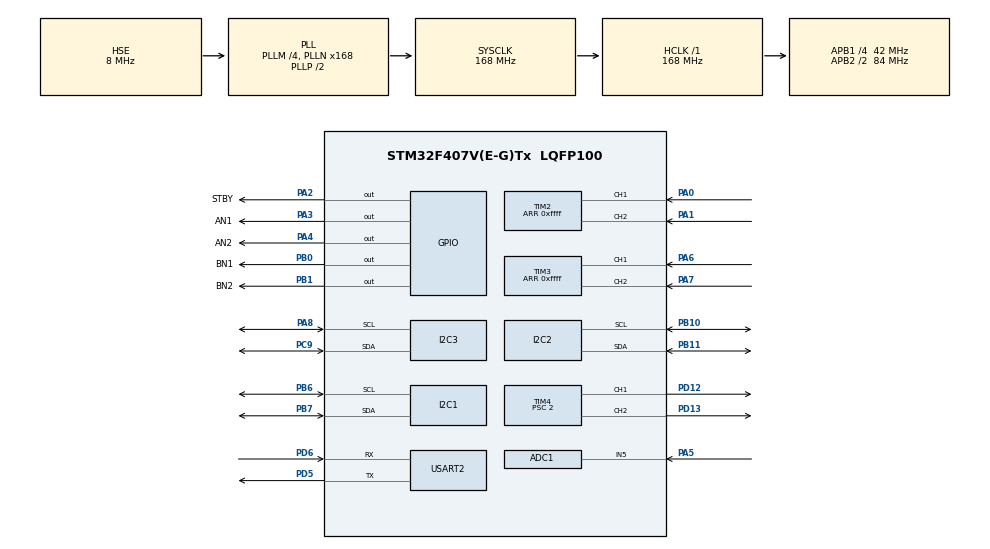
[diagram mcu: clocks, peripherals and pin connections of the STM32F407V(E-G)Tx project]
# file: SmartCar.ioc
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ADC1.Channel-0\#ChannelRegularConversion=ADC_CHANNEL_5
ADC1.ContinuousConvMode=ENABLE
ADC1.DMAContinuousRequests=ENABLE
ADC1.NbrOfConversionFlag=1
ADC1.Rank-0\#ChannelRegularConversion=1
ADC1.SamplingTime-0\#ChannelRegularConversion=ADC_SAMPLETIME_15CYCLES
ADC1.master=1
Dma.ADC1.0.Direction=DMA_PERIPH_TO_MEMORY
Dma.ADC1.0.FIFOMode=DMA_FIFOMODE_DISABLE
Dma.ADC1.0.Instance=DMA2_Stream0
Dma.ADC1.0.MemDataAlignment=DMA_MDATAALIGN_WORD
Dma.ADC1.0.MemInc=DMA_MINC_ENABLE
Dma.ADC1.0.Mode=DMA_NORMAL
Dma.ADC1.0.PeriphDataAlignment=DMA_PDATAALIGN_WORD
Dma.ADC1.0.PeriphInc=DMA_PINC_DISABLE
Dma.ADC1.0.Priority=DMA_PRIORITY_LOW
Dma.Request0=ADC1
Dma.Request1=USART2_RX
Dma.USART2_RX.1.Direction=DMA_PERIPH_TO_MEMORY
Dma.USART2_RX.1.FIFOMode=DMA_FIFOMODE_DISABLE
Dma.USART2_RX.1.Instance=DMA1_Stream5
Dma.USART2_RX.1.MemDataAlignment=DMA_MDATAALIGN_BYTE
Dma.USART2_RX.1.MemInc=DMA_MINC_ENABLE
Dma.USART2_RX.1.Mode=DMA_NORMAL
Dma.USART2_RX.1.PeriphDataAlignment=DMA_PDATAALIGN_BYTE
Dma.USART2_RX.1.PeriphInc=DMA_PINC_DISABLE
Dma.USART2_RX.1.Priority=DMA_PRIORITY_LOW
I2C1.I2C_Mode=I2C_Fast
Mcu.Family=STM32F4
Mcu.Name=STM32F407V(E-G)Tx
Mcu.Package=LQFP100
NVIC.DMA1_Stream5_IRQn=true\:0\:0\:false\:false\:true\:false\:true\:true
NVIC.DMA2_Stream0_IRQn=true\:0\:0\:false\:false\:true\:false\:true\:true
NVIC.PriorityGroup=NVIC_PRIORITYGROUP_4
NVIC.TIM2_IRQn=true\:0\:0\:false\:false\:true\:true\:true\:true
NVIC.TIM3_IRQn=true\:0\:0\:false\:false\:true\:true\:true\:true
NVIC.USART2_IRQn=true\:0\:0\:false\:false\:true\:true\:true\:true
PA0-WKUP.Signal=S_TIM2_CH1_ETR
PA1.Signal=S_TIM2_CH2
PA13.Mode=Serial_Wire
PA13.Signal=SYS_JTMS-SWDIO
PA14.Mode=Serial_Wire
PA14.Signal=SYS_JTCK-SWCLK
PA2.GPIO_Label=STBY
PA2.Signal=GPIO_Output
PA3.GPIO_Label=AN1
PA3.Signal=GPIO_Output
PA4.GPIO_Label=AN2
PA4.Signal=GPIO_Output
PA5.Signal=ADCx_IN5
PA6.Signal=S_TIM3_CH1
PA7.Signal=S_TIM3_CH2
PA8.Mode=I2C
PA8.Signal=I2C3_SCL
PB0.GPIO_Label=BN1
PB0.Signal=GPIO_Output
PB1.GPIO_Label=BN2
PB1.Signal=GPIO_Output
PB10.GPIO_Pu=GPIO_PULLUP
PB10.Mode=I2C
PB10.Signal=I2C2_SCL
PB11.GPIO_Pu=GPIO_PULLUP
PB11.Mode=I2C
PB11.Signal=I2C2_SDA
PB6.Mode=I2C
PB6.Signal=I2C1_SCL
PB7.Mode=I2C
PB7.Signal=I2C1_SDA
PC14-OSC32_IN.Mode=LSE-External-Oscillator
PC14-OSC32_IN.Signal=RCC_OSC32_IN
PC15-OSC32_OUT.Mode=LSE-External-Oscillator
PC15-OSC32_OUT.Signal=RCC_OSC32_OUT
PC9.Mode=I2C
PC9.Signal=I2C3_SDA
PD12.Signal=S_TIM4_CH1
PD13.Signal=S_TIM4_CH2
PD5.Mode=Asynchronous
PD5.Signal=USART2_TX
PD6.Mode=Asynchronous
PD6.Signal=USART2_RX
PH0-OSC_IN.Mode=HSE-External-Oscillator
PH0-OSC_IN.Signal=RCC_OSC_IN
PH1-OSC_OUT.Mode=HSE-External-Oscillator
PH1-OSC_OUT.Signal=RCC_OSC_OUT
ProjectManager.HeapSize=0x200
ProjectManager.StackSize=0x400
ProjectManager.TargetToolchain=CMake
RCC.48MHZClocksFreq_Value=84000000
RCC.AHBFreq_Value=168000000
RCC.APB1CLKDivider=RCC_HCLK_DIV4
RCC.APB1Freq_Value=42000000
RCC.APB1TimFreq_Value=84000000
RCC.APB2CLKDivider=RCC_HCLK_DIV2
RCC.APB2Freq_Value=84000000
RCC.APB2TimFreq_Value=168000000
RCC.CortexFreq_Value=168000000
RCC.HCLKFreq_Value=168000000
RCC.HSE_VALUE=8000000
RCC.HSI_VALUE=16000000
RCC.PLLM=4
RCC.PLLN=168
RCC.PLLSourceVirtual=RCC_PLLSOURCE_HSE
RCC.SYSCLKFreq_VALUE=168000000
RCC.SYSCLKSource=RCC_SYSCLKSOURCE_PLLCLK
RCC.VCOOutputFreq_Value=336000000
SH.ADCx_IN5.0=ADC1_IN5,IN5
SH.S_TIM2_CH1_ETR.0=TIM2_CH1,Encoder_Interface
SH.S_TIM2_CH2.0=TIM2_CH2,Encoder_Interface
SH.S_TIM3_CH1.0=TIM3_CH1,Encoder_Interface
SH.S_TIM3_CH2.0=TIM3_CH2,Encoder_Interface
SH.S_TIM4_CH1.0=TIM4_CH1,PWM Generation1 CH1
SH.S_TIM4_CH2.0=TIM4_CH2,PWM Generation2 CH2
TIM2.EncoderMode=TIM_ENCODERMODE_TI12
TIM2.IC2Polarity=TIM_ICPOLARITY_FALLING
TIM2.Period=0xffff
TIM3.EncoderMode=TIM_ENCODERMODE_TI12
TIM3.IC2Polarity=TIM_ICPOLARITY_FALLING
TIM3.Period=0xffff
TIM4.Channel-PWM\ Generation1\ CH1=TIM_CHANNEL_1
TIM4.Channel-PWM\ Generation2\ CH2=TIM_CHANNEL_2
TIM4.Period=999
TIM4.Prescaler=2
USART2.VirtualMode=VM_ASYNC
VP_TIM4_VS_ClockSourceINT.Mode=Internal
board=custom

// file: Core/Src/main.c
/* USER CODE BEGIN Header */
/**
  ******************************************************************************
  * @file           : main.c
  * @brief          : Main program body
  ******************************************************************************
  * @attention
  *
  * Copyright (c) 2025 STMicroelectronics.
  * All rights reserved.
  *
  * This software is licensed under terms that can be found in the LICENSE file
  * in the root directory of this software component.
  * If no LICENSE file comes with this software, it is provided AS-IS.
  *
  ******************************************************************************
  */
/* USER CODE END Header */
#include "main.h"
#include "adc.h"
#include "dma.h"
#include "i2c.h"
#include "tim.h"
#include "usart.h"
#include "gpio.h"

/* USER CODE BEGIN Includes */
#include "mydefine.h"
/* USER CODE END Includes */

void SystemClock_Config(void);

int main(void)
{

  /* MCU Configuration--------------------------------------------------------*/

  /* Reset of all peripherals, Initializes the Flash interface and the Systick. */
  HAL_Init();

  /* Configure the system clock */
  SystemClock_Config();

  /* Initialize all configured peripherals */
  MX_GPIO_Init();
  MX_DMA_Init();
  MX_I2C1_Init();
  MX_I2C2_Init();
  MX_ADC1_Init();
  MX_TIM2_Init();
  MX_TIM3_Init();
  MX_TIM4_Init();
  MX_I2C3_Init();
  MX_USART2_UART_Init();
  /* USER CODE BEGIN 2 */
  IMU_Init();
  Encoder_Init();
  OLED_Init();
  gary_init();
  PID_init();
  Motor_Create(&motor1,&htim4,TIM_CHANNEL_1,GPIOA,AN1_Pin,GPIOA,AN2_Pin,GPIOA,STBY_Pin); // 左轮正向
  Motor_Create(&motor2,&htim4,TIM_CHANNEL_2,GPIOB,BN1_Pin,GPIOB,BN2_Pin,GPIOA,STBY_Pin); // 右轮正向
  scheduler_init();
  /* USER CODE END 2 */

  /* Infinite loop */
  /* USER CODE BEGIN WHILE */
  while (1)
  {
    scheduler_run();
    /* USER CODE END WHILE */

  }
}

void SystemClock_Config(void)
{
  RCC_OscInitTypeDef RCC_OscInitStruct = {0};
  RCC_ClkInitTypeDef RCC_ClkInitStruct = {0};

  /** Configure the main internal regulator output voltage
  */
  __HAL_RCC_PWR_CLK_ENABLE();
  __HAL_PWR_VOLTAGESCALING_CONFIG(PWR_REGULATOR_VOLTAGE_SCALE1);

  /** Initializes the RCC Oscillators according to the specified parameters
  * in the RCC_OscInitTypeDef structure.
  */
  RCC_OscInitStruct.OscillatorType = RCC_OSCILLATORTYPE_HSE;
  RCC_OscInitStruct.HSEState = RCC_HSE_ON;
  RCC_OscInitStruct.PLL.PLLState = RCC_PLL_ON;
  RCC_OscInitStruct.PLL.PLLSource = RCC_PLLSOURCE_HSE;
  RCC_OscInitStruct.PLL.PLLM = 4;
  RCC_OscInitStruct.PLL.PLLN = 168;
  RCC_OscInitStruct.PLL.PLLP = RCC_PLLP_DIV2;
  RCC_OscInitStruct.PLL.PLLQ = 4;
  if (HAL_RCC_OscConfig(&RCC_OscInitStruct) != HAL_OK)
  {
    Error_Handler();
  }

  /** Initializes the CPU, AHB and APB buses clocks
  */
  RCC_ClkInitStruct.ClockType = RCC_CLOCKTYPE_HCLK|RCC_CLOCKTYPE_SYSCLK
                              |RCC_CLOCKTYPE_PCLK1|RCC_CLOCKTYPE_PCLK2;
  RCC_ClkInitStruct.SYSCLKSource = RCC_SYSCLKSOURCE_PLLCLK;
  RCC_ClkInitStruct.AHBCLKDivider = RCC_SYSCLK_DIV1;
  RCC_ClkInitStruct.APB1CLKDivider = RCC_HCLK_DIV4;
  RCC_ClkInitStruct.APB2CLKDivider = RCC_HCLK_DIV2;

  if (HAL_RCC_ClockConfig(&RCC_ClkInitStruct, FLASH_LATENCY_5) != HAL_OK)
  {
    Error_Handler();
  }
}

void Error_Handler(void)
{
  __disable_irq();
  while (1)
  {
  }
}
